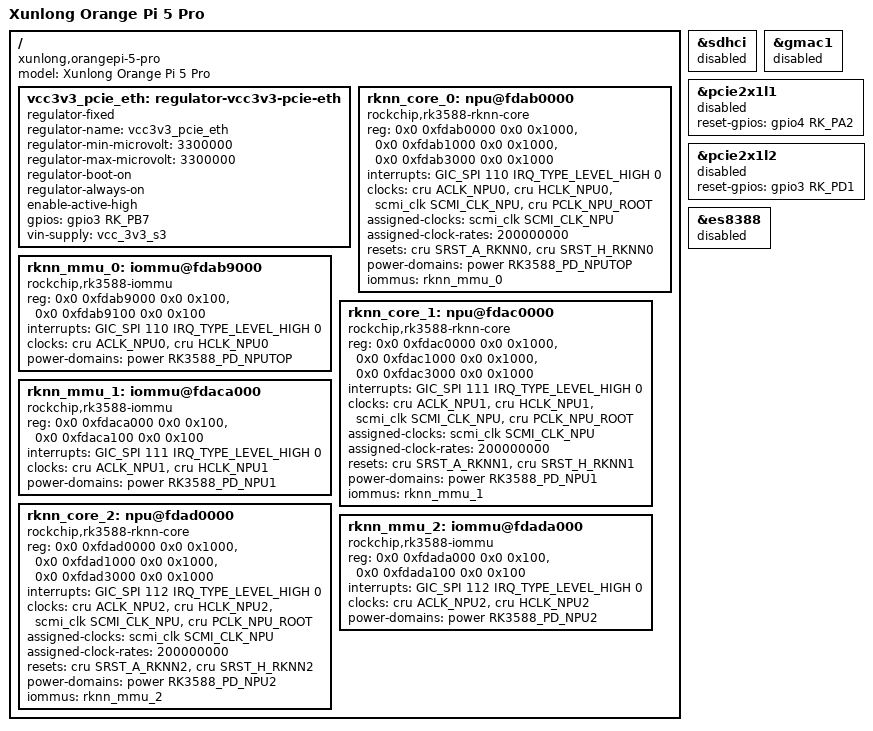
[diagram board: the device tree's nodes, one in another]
// SPDX-License-Identifier: (GPL-2.0+ OR MIT)
//
// Orange Pi 5 Pro — based on upstream Orange Pi 5 DTSI.
// The 5 Pro shares the RK3588S SoC and most peripherals with the non-Pro.
// Board-level differences: PCIe Ethernet (vs RGMII), onboard WiFi, eMMC.
//
// TODO: Remove this file once rk3588s-orangepi-5-pro.dts is merged upstream.

/dts-v1/;

#include "upstream/src/arm64/rockchip/rk3588s-orangepi-5.dtsi"

/ {
	model = "Xunlong Orange Pi 5 Pro";
	compatible = "xunlong,orangepi-5-pro", "rockchip,rk3588s";

	/* 3.3 V rail for PCIe Ethernet NIC — active-high enable on GPIO3_B7 */
	vcc3v3_pcie_eth: regulator-vcc3v3-pcie-eth {
		compatible = "regulator-fixed";
		regulator-name = "vcc3v3_pcie_eth";
		regulator-min-microvolt = <3300000>;
		regulator-max-microvolt = <3300000>;
		regulator-boot-on;
		regulator-always-on;
		enable-active-high;
		gpios = <&gpio3 RK_PB7 GPIO_ACTIVE_HIGH>;
		vin-supply = <&vcc_3v3_s3>;
	};

	rknn_core_0: npu@fdab0000 {
		compatible = "rockchip,rk3588-rknn-core";
		reg = <0x0 0xfdab0000 0x0 0x1000>,
		      <0x0 0xfdab1000 0x0 0x1000>,
		      <0x0 0xfdab3000 0x0 0x1000>;
		reg-names = "pc", "cna", "core";
		interrupts = <GIC_SPI 110 IRQ_TYPE_LEVEL_HIGH 0>;
		clocks = <&cru ACLK_NPU0>, <&cru HCLK_NPU0>,
			 <&scmi_clk SCMI_CLK_NPU>, <&cru PCLK_NPU_ROOT>;
		clock-names = "aclk", "hclk", "npu", "pclk";
		assigned-clocks = <&scmi_clk SCMI_CLK_NPU>;
		assigned-clock-rates = <200000000>;
		resets = <&cru SRST_A_RKNN0>, <&cru SRST_H_RKNN0>;
		reset-names = "srst_a", "srst_h";
		power-domains = <&power RK3588_PD_NPUTOP>;
		iommus = <&rknn_mmu_0>;
		status = "okay";
	};

	rknn_mmu_0: iommu@fdab9000 {
		compatible = "rockchip,rk3588-iommu", "rockchip,rk3568-iommu";
		reg = <0x0 0xfdab9000 0x0 0x100>,
		      <0x0 0xfdab9100 0x0 0x100>;
		interrupts = <GIC_SPI 110 IRQ_TYPE_LEVEL_HIGH 0>;
		clocks = <&cru ACLK_NPU0>, <&cru HCLK_NPU0>;
		clock-names = "aclk", "iface";
		power-domains = <&power RK3588_PD_NPUTOP>;
		#iommu-cells = <0>;
		status = "okay";
	};

	rknn_core_1: npu@fdac0000 {
		compatible = "rockchip,rk3588-rknn-core";
		reg = <0x0 0xfdac0000 0x0 0x1000>,
		      <0x0 0xfdac1000 0x0 0x1000>,
		      <0x0 0xfdac3000 0x0 0x1000>;
		reg-names = "pc", "cna", "core";
		interrupts = <GIC_SPI 111 IRQ_TYPE_LEVEL_HIGH 0>;
		clocks = <&cru ACLK_NPU1>, <&cru HCLK_NPU1>,
			 <&scmi_clk SCMI_CLK_NPU>, <&cru PCLK_NPU_ROOT>;
		clock-names = "aclk", "hclk", "npu", "pclk";
		assigned-clocks = <&scmi_clk SCMI_CLK_NPU>;
		assigned-clock-rates = <200000000>;
		resets = <&cru SRST_A_RKNN1>, <&cru SRST_H_RKNN1>;
		reset-names = "srst_a", "srst_h";
		power-domains = <&power RK3588_PD_NPU1>;
		iommus = <&rknn_mmu_1>;
		status = "okay";
	};

	rknn_mmu_1: iommu@fdaca000 {
		compatible = "rockchip,rk3588-iommu", "rockchip,rk3568-iommu";
		reg = <0x0 0xfdaca000 0x0 0x100>,
		      <0x0 0xfdaca100 0x0 0x100>;
		interrupts = <GIC_SPI 111 IRQ_TYPE_LEVEL_HIGH 0>;
		clocks = <&cru ACLK_NPU1>, <&cru HCLK_NPU1>;
		clock-names = "aclk", "iface";
		power-domains = <&power RK3588_PD_NPU1>;
		#iommu-cells = <0>;
		status = "okay";
	};

	rknn_core_2: npu@fdad0000 {
		compatible = "rockchip,rk3588-rknn-core";
		reg = <0x0 0xfdad0000 0x0 0x1000>,
		      <0x0 0xfdad1000 0x0 0x1000>,
		      <0x0 0xfdad3000 0x0 0x1000>;
		reg-names = "pc", "cna", "core";
		interrupts = <GIC_SPI 112 IRQ_TYPE_LEVEL_HIGH 0>;
		clocks = <&cru ACLK_NPU2>, <&cru HCLK_NPU2>,
			 <&scmi_clk SCMI_CLK_NPU>, <&cru PCLK_NPU_ROOT>;
		clock-names = "aclk", "hclk", "npu", "pclk";
		assigned-clocks = <&scmi_clk SCMI_CLK_NPU>;
		assigned-clock-rates = <200000000>;
		resets = <&cru SRST_A_RKNN2>, <&cru SRST_H_RKNN2>;
		reset-names = "srst_a", "srst_h";
		power-domains = <&power RK3588_PD_NPU2>;
		iommus = <&rknn_mmu_2>;
		status = "okay";
	};

	rknn_mmu_2: iommu@fdada000 {
		compatible = "rockchip,rk3588-iommu", "rockchip,rk3568-iommu";
		reg = <0x0 0xfdada000 0x0 0x100>,
		      <0x0 0xfdada100 0x0 0x100>;
		interrupts = <GIC_SPI 112 IRQ_TYPE_LEVEL_HIGH 0>;
		clocks = <&cru ACLK_NPU2>, <&cru HCLK_NPU2>;
		clock-names = "aclk", "iface";
		power-domains = <&power RK3588_PD_NPU2>;
		#iommu-cells = <0>;
		status = "okay";
	};
};

/* eMMC — enabled on the Pro (disabled in shared dtsi) */
&sdhci {
	status = "disabled";
};

/* GMAC — Pro uses RGMII Motorcomm PHY. Enable SoC GMAC. */
&gmac1 {
	status = "disabled";
};

/* PCIe 2.0 x1 lane 1 (pcie2x1l1 @ fe180000) */
&pcie2x1l1 {
	reset-gpios = <&gpio4 RK_PA2 GPIO_ACTIVE_HIGH>;
	status = "disabled";
};

/* PCIe 2.0 x1 lane 2 (pcie2x1l2 @ fe190000) — Ethernet NIC */
&pcie2x1l2 {
	reset-gpios = <&gpio3 RK_PD1 GPIO_ACTIVE_HIGH>;
	status = "disabled";
};

/* Disable audio codec to prevent I2C timeouts */
&es8388 {
	status = "disabled";
};

